# WLR089U0 register map
Vendor: Microchip
Registers are 32-bit, read-write, reset 0x0 unless marked. A register's access mark holds for its fields unless they carry their own. Addresses are absolute, and some are shared; only a register's first bit layout is shown; [hi:lo] are bit positions; {n}, {i} and the like mark numbered series; 'fields as' and 'values as' point back to an identical list.

## WDT
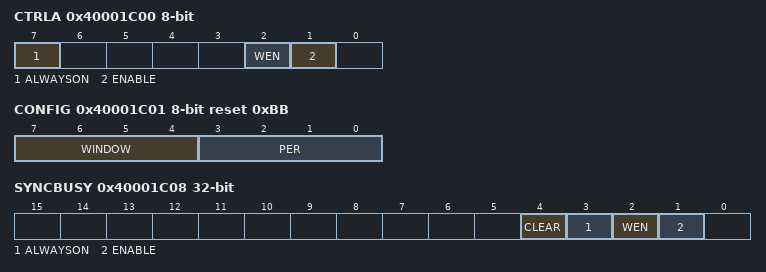
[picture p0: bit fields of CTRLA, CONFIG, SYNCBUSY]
0x40001C00 CTRLA 8-bit
  [7] ALWAYSON
  [2] WEN — Watchdog Timer Window Mode Enable
  [1] ENABLE
0x40001C01 CONFIG 8-bit reset 0xBB
  [7:4] WINDOW — Window Mode Time-Out Period
    0=CYC8 (8 clock cycles); 1=CYC16 (16 clock cycles); 2=CYC32 (32 clock cycles); 3=CYC64 (64 clock cycles); 4=CYC128 (128 clock cycles); 5=CYC256 (256 clock cycles); 6=CYC512 (512 clock cycles); 7=CYC1024 (1024 clock cycles); 8=CYC2048 (2048 clock cycles); 9=CYC4096 (4096 clock cycles); 10=CYC8192 (8192 clock cycles); 11=CYC16384 (16384 clock cycles)
  [3:0] PER — Time-Out Period
    values as WINDOW
0x40001C02 EWCTRL 8-bit reset 0xB
  [3:0] EWOFFSET — Early Warning Interrupt Time Offset
    values as CONFIG.WINDOW
0x40001C04 INTENCLR 8-bit
  [0] EW — Early Warning Interrupt Enable
0x40001C05 INTENSET 8-bit
  [0] EW — Early Warning Interrupt Enable
0x40001C06 INTFLAG 8-bit
  [0] EW — Early Warning
0x40001C08 SYNCBUSY ro
  [4] CLEAR — Clear Busy
  [3] ALWAYSON — Always-On Busy
  [2] WEN — Window Enable Busy
  [1] ENABLE — Enable Busy
0x40001C0C CLEAR 8-bit wo
  [7:0] CLEAR — Watchdog Clear
    165=KEY (Clear Key)

## RTC
0x4000200E DBGCTRL 8-bit
  [0] DBGRUN — Run During Debug
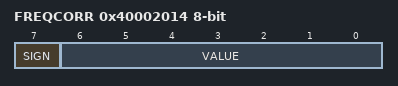
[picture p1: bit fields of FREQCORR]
0x40002014 FREQCORR 8-bit
  [7] SIGN — Correction Sign
  [6:0] VALUE — Correction Value
0x40002040 GP0
  [31:0] GP — General Purpose
0x40002044 GP1
  [31:0] GP — General Purpose

## EIC
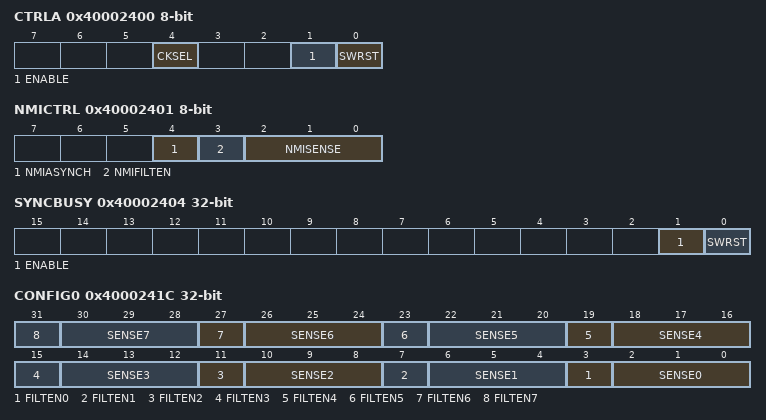
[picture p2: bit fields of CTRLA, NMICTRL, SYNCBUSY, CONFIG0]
0x40002400 CTRLA 8-bit
  [4] CKSEL — Clock Selection
    0=CLK_GCLK (Clocked by GCLK); 1=CLK_ULP32K (Clocked by ULP32K)
  [1] ENABLE
  [0] SWRST — Software Reset
0x40002401 NMICTRL 8-bit
  [4] NMIASYNCH — NMI Asynchronous edge Detection Enable
    0=SYNC (Edge detection is clock synchronously operated); 1=ASYNC (Edge detection is clock asynchronously operated)
  [3] NMIFILTEN — NMI Filter Enable
  [2:0] NMISENSE — NMI Input Sense Configuration
    0=NONE (No detection); 1=RISE (Rising edge detection); 2=FALL (Falling edge detection); 3=BOTH (Both edges detection); 4=HIGH (High level detection); 5=LOW (Low level detection)
0x40002402 NMIFLAG 16-bit
  [0] NMI — NMI Interrupt Flag
0x40002404 SYNCBUSY ro
  [1] ENABLE — Enable synchronisation
  [0] SWRST — Software reset synchronisation
0x40002408 EVCTRL
  [15:0] EXTINTEO — External Interrupt Event Output Enable
0x4000240C INTENCLR
  [15:0] EXTINT — External Interrupt Disable
0x40002410 INTENSET
  [15:0] EXTINT — External Interrupt Enable
0x40002414 INTFLAG
  [15:0] EXTINT — External Interrupt Flag
0x40002418 ASYNCH
  [15:0] ASYNCH — EIC Asynchronous edge Detection Enable
    values as NMICTRL.NMIASYNCH
0x4000241C CONFIG0
  [4n+3] FILTEN{n} (n=0..7) — Filter Enable {n}
  [4n+2:4n] SENSE{n} (n=0..7) — Input Sense Configuration {n}
    values as NMICTRL.NMISENSE
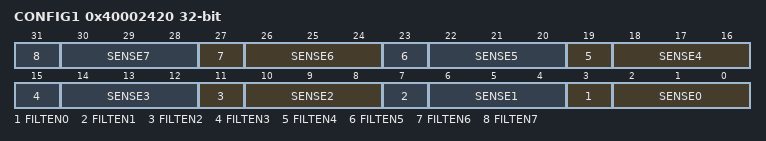
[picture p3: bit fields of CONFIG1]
0x40002420 CONFIG1
  fields as CONFIG0

## PORT
{0x40002800+0x80*i} GROUP{i}DIR (i=0..2)
  [31:0] DIR — Port Data Direction
{0x40002804+0x80*i} GROUP{i}DIRCLR (i=0..2)
  [31:0] DIRCLR — Port Data Direction Clear
{0x40002808+0x80*i} GROUP{i}DIRSET (i=0..2)
  [31:0] DIRSET — Port Data Direction Set
{0x4000280C+0x80*i} GROUP{i}DIRTGL (i=0..2)
  [31:0] DIRTGL — Port Data Direction Toggle
{0x40002810+0x80*i} GROUP{i}OUT (i=0..2)
  [31:0] OUT — Port Data Output Value
{0x40002814+0x80*i} GROUP{i}OUTCLR (i=0..2)
  [31:0] OUTCLR — Port Data Output Value Clear
{0x40002818+0x80*i} GROUP{i}OUTSET (i=0..2)
  [31:0] OUTSET — Port Data Output Value Set
{0x4000281C+0x80*i} GROUP{i}OUTTGL (i=0..2)
  [31:0] OUTTGL — Port Data Output Value Toggle
{0x40002820+0x80*i} GROUP{i}IN ro (i=0..2)
  [31:0] IN — Port Data Input Value
{0x40002824+0x80*i} GROUP{i}CTRL (i=0..2)
  [31:0] SAMPLING — Input Sampling Mode
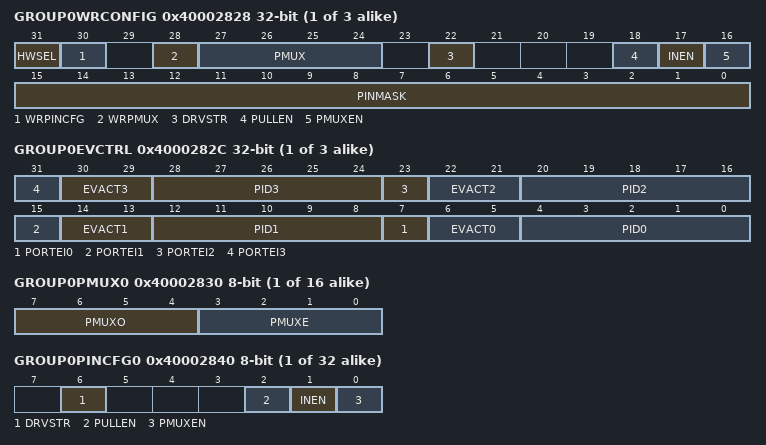
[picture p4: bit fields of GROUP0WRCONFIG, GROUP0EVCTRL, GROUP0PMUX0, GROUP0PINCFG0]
{0x40002828+0x80*i} GROUP{i}WRCONFIG wo (i=0..2)
  [31] HWSEL — Half-Word Select
  [30] WRPINCFG — Write PINCFG Registers
  [28] WRPMUX — Write PMUX Registers
  [27:24] PMUX — Peripheral Multiplexing Template
  [22] DRVSTR — Output Driver Strength Selection
  [18] PULLEN — Pull Enable
  [17] INEN — Input Enable
  [16] PMUXEN — Select Peripheral Multiplexer
  [15:0] PINMASK — Pin Mask for Multiple Pin Configuration
{0x4000282C+0x80*i} GROUP{i}EVCTRL (i=0..2)
  [8n+7] PORTEI{n} (n=0..3) — Port Event Enable Input {n}
  [30:29] EVACT3 — Port Event Action 3
  [8n+4:8n] PID{n} (n=0..3) — Port Event Pin Identifier {n}
  [22:21] EVACT2 — Port Event Action 2
  [14:13] EVACT1 — Port Event Action 1
  [6:5] EVACT0 — Port Event Action 0
    0=OUT (Event output to pin); 1=SET (Set output register of pin on event); 2=CLR (Clear output register of pin on event); 3=TGL (Toggle output register of pin on event)
{0x40002830+i} GROUP0PMUX{i} 8-bit (i=0..15)
  [7:4] PMUXO — Peripheral Multiplexing for Odd-Numbered Pin
    0=A (Peripheral function A selected); 1=B (Peripheral function B selected); 2=C (Peripheral function C selected); 3=D (Peripheral function D selected); 4=E (Peripheral function E selected); 5=F (Peripheral function F selected); 6=G (Peripheral function G selected); 7=H (Peripheral function H selected); 8=I (Peripheral function I selected)
  [3:0] PMUXE — Peripheral Multiplexing for Even-Numbered Pin
    values as PMUXO
{0x40002840+i} GROUP0PINCFG{i} 8-bit (i=0..31)
  [6] DRVSTR — Output Driver Strength Selection
  [2] PULLEN — Pull Enable
  [1] INEN — Input Enable
  [0] PMUXEN — Select Peripheral Multiplexer
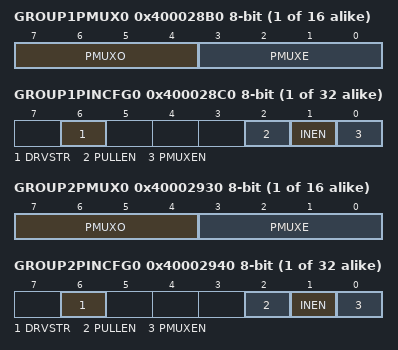
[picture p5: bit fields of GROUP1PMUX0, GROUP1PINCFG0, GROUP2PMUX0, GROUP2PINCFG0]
{0x400028B0+i} GROUP1PMUX{i} 8-bit (i=0..15)
  fields as GROUP0PMUX0
{0x400028C0+i} GROUP1PINCFG{i} 8-bit (i=0..31)
  fields as GROUP0PINCFG0
{0x40002930+i} GROUP2PMUX{i} 8-bit (i=0..15)
  fields as GROUP0PMUX0
{0x40002940+i} GROUP2PINCFG{i} 8-bit (i=0..31)
  fields as GROUP0PINCFG0
